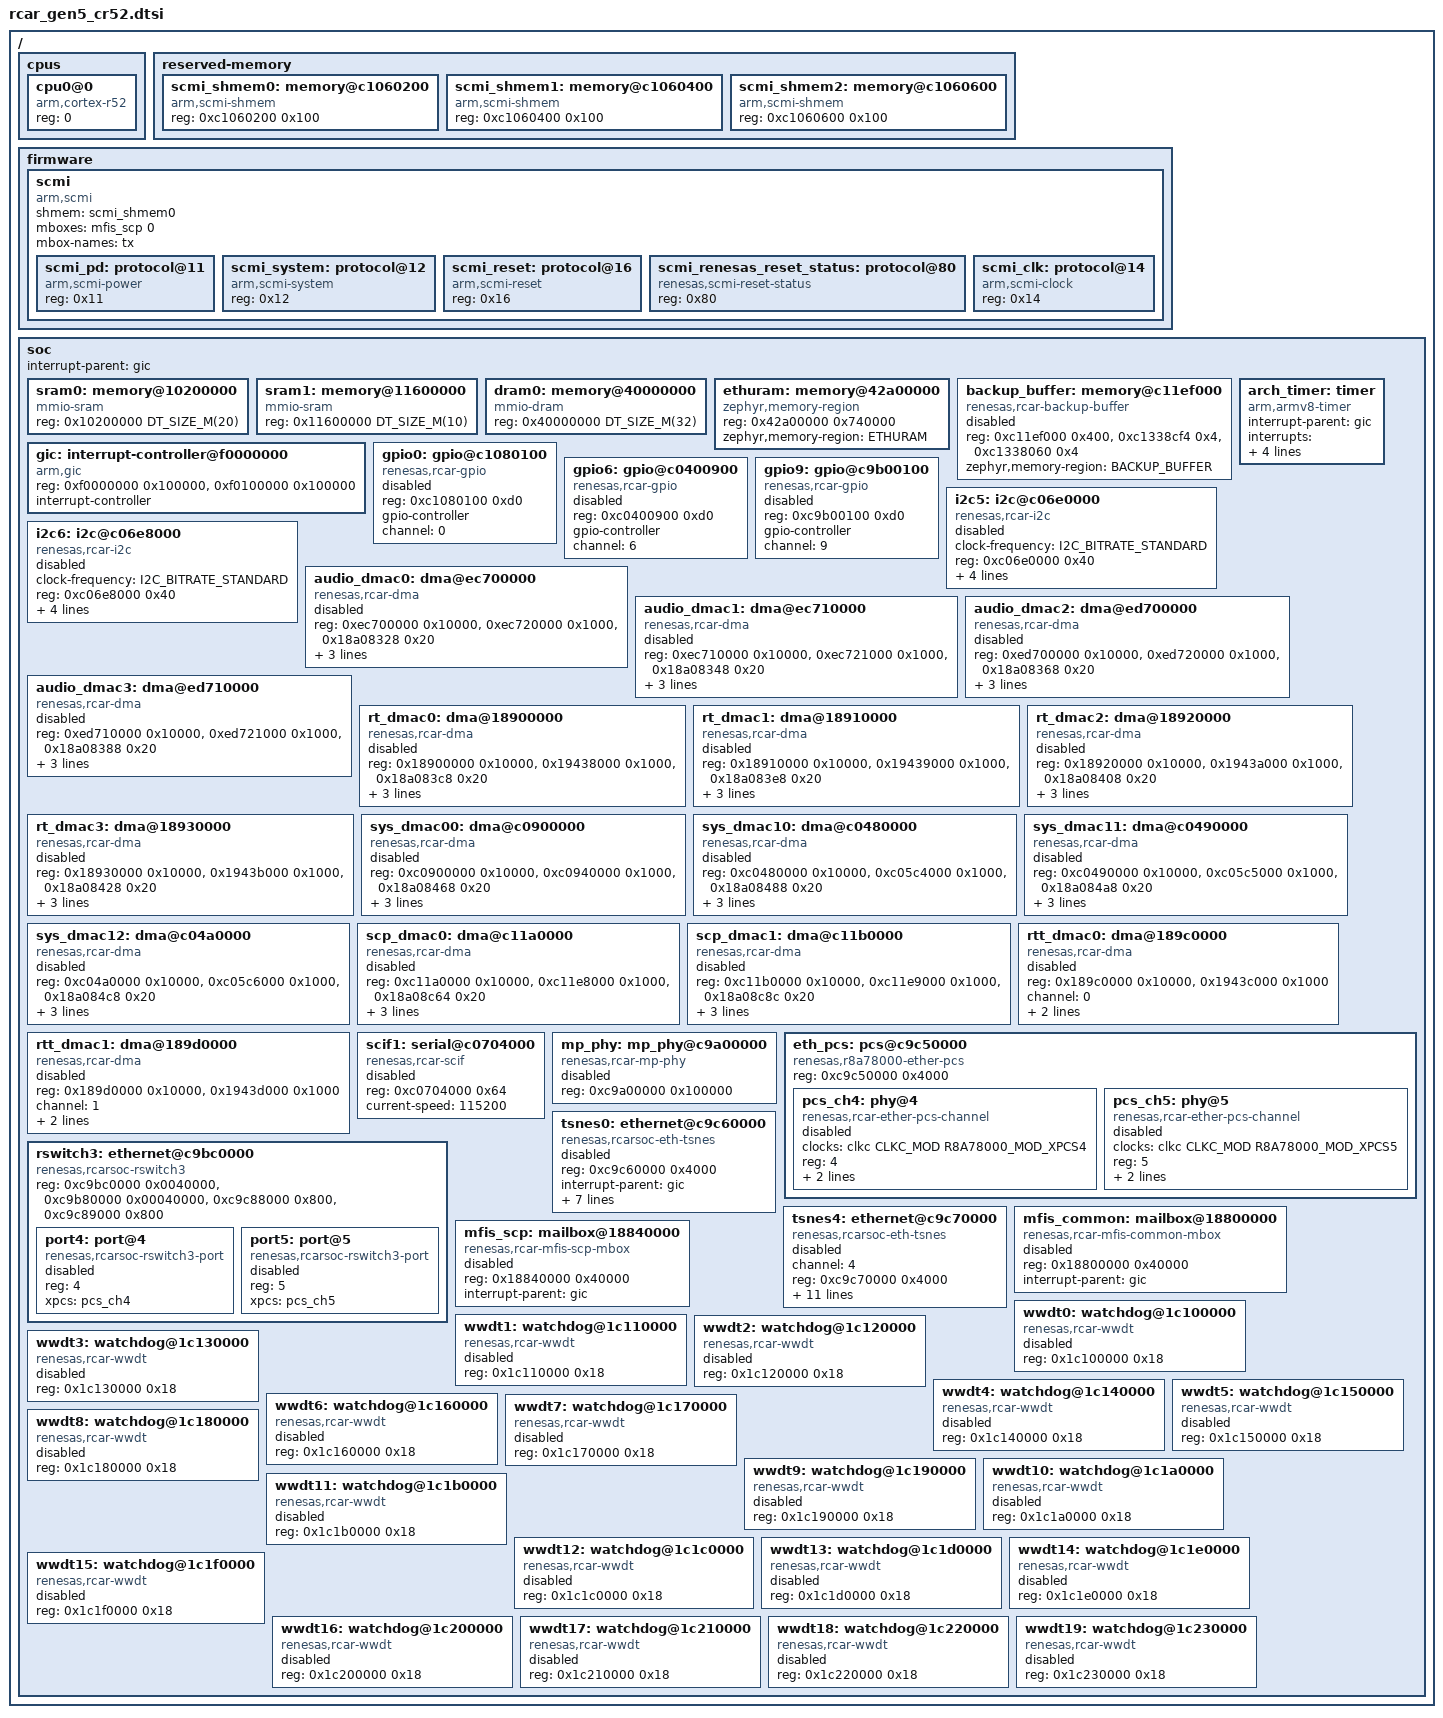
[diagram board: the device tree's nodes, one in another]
/*
 * Copyright (c) 2026 Renesas Electronics Corporation
 *
 * SPDX-License-Identifier: Apache-2.0
 */

#include <arm/armv8-r.dtsi>
#include <zephyr/dt-bindings/dt-util.h>
#include <zephyr/dt-bindings/interrupt-controller/arm-gic.h>
#include <zephyr/dt-bindings/clock/r8a78000_clkc_mdlc.h>
#include <zephyr/dt-bindings/clock/r8a78000_scmi_clock.h>
#include <zephyr/dt-bindings/i2c/i2c.h>
#include <mem.h>

/ {
	cpus {
		#address-cells = <1>;
		#size-cells = <0>;

		cpu0@0 {
			device_type = "cpu";
			compatible = "arm,cortex-r52";
			reg = <0>;
		};
	};

	reserved-memory {
		#address-cells = <1>;
		#size-cells = <1>;

		scmi_shmem0: memory@c1060200 {
			compatible = "arm,scmi-shmem";
			reg = <0xc1060200 0x100>;
		};

		scmi_shmem1: memory@c1060400 {
			compatible = "arm,scmi-shmem";
			reg = <0xc1060400 0x100>;
		};

		scmi_shmem2: memory@c1060600 {
			compatible = "arm,scmi-shmem";
			reg = <0xc1060600 0x100>;
		};
	};

	firmware {
		scmi {
			compatible = "arm,scmi";
			shmem = <&scmi_shmem0>;
			mboxes = <&mfis_scp 0>;
			mbox-names = "tx";

			#address-cells = <1>;
			#size-cells = <0>;

			scmi_pd: protocol@11 {
				compatible = "arm,scmi-power";
				reg = <0x11>;
				#power-domain-cells = <1>;
			};

			scmi_system: protocol@12 {
				compatible = "arm,scmi-system";
				reg = <0x12>;
			};

			scmi_reset: protocol@16 {
				compatible = "arm,scmi-reset";
				reg = <0x16>;
				#reset-cells = <1>;
			};

			scmi_renesas_reset_status: protocol@80 {
				compatible = "renesas,scmi-reset-status";
				reg = <0x80>;
			};

			scmi_clk: protocol@14 {
				compatible = "arm,scmi-clock";
				reg = <0x14>;
				#clock-cells = <1>;
			};
		};
	};

	soc {
		interrupt-parent = <&gic>;

		sram0: memory@10200000 {
			compatible = "mmio-sram";
			reg = <0x10200000 DT_SIZE_M(20)>;
		};

		sram1: memory@11600000 {
			compatible = "mmio-sram";
			reg = <0x11600000 DT_SIZE_M(10)>;
		};

		dram0: memory@40000000 {
			compatible = "mmio-dram";
			reg = <0x40000000 DT_SIZE_M(32)>;
		};

		ethuram: memory@42a00000 {
			compatible = "zephyr,memory-region";
			reg = <0x42a00000 0x740000>;
			zephyr,memory-region = "ETHURAM";
			status = "okay";
		};

		backup_buffer: memory@c11ef000 {
			compatible = "renesas,rcar-backup-buffer", "zephyr,memory-region";
			/* BKBUF, MDLC27PKCPROT1, MDLC27BKBAPR */
			reg = <0xc11ef000 0x400>,
			      <0xc1338cf4 0x4>,
			      <0xc1338060 0x4>;
			reg-names = "bkbuf", "prot", "bkbapr";
			zephyr,memory-region = "BACKUP_BUFFER";
			status = "disabled";
		};

		gic: interrupt-controller@f0000000 {
			compatible = "arm,gic", "arm,gic-v3";
			reg = <0xf0000000 0x100000>,
			      <0xf0100000 0x100000>;
			interrupt-controller;
			#interrupt-cells = <4>;
			status = "okay";
		};

		arch_timer: timer {
			compatible = "arm,armv8-timer";
			interrupt-parent = <&gic>;
			interrupts = <GIC_PPI 13 IRQ_TYPE_LEVEL IRQ_DEFAULT_PRIORITY>,
				     <GIC_PPI 14 IRQ_TYPE_LEVEL IRQ_DEFAULT_PRIORITY>,
				     <GIC_PPI 11 IRQ_TYPE_LEVEL IRQ_DEFAULT_PRIORITY>,
				     <GIC_PPI 10 IRQ_TYPE_LEVEL IRQ_DEFAULT_PRIORITY>;
		};

		gpio0: gpio@c1080100 {
			compatible = "renesas,rcar-gpio";
			reg = <0xc1080100 0xd0>;
			#gpio-cells = <2>;
			gpio-controller;
			channel = <0>;
			status = "disabled";
		};

		gpio6: gpio@c0400900 {
			compatible = "renesas,rcar-gpio";
			reg = <0xc0400900 0xd0>;
			#gpio-cells = <2>;
			gpio-controller;
			channel = <6>;
			status = "disabled";
		};

		gpio9: gpio@c9b00100 {
			compatible = "renesas,rcar-gpio";
			reg = <0xc9b00100 0xd0>;
			#gpio-cells = <2>;
			gpio-controller;
			channel = <9>;
			status = "disabled";
		};

		i2c5: i2c@c06e0000 {
			compatible = "renesas,rcar-i2c";
			clock-frequency = <I2C_BITRATE_STANDARD>;
			#address-cells = <1>;
			#size-cells = <0>;
			reg = <0xc06e0000 0x40>;
			interrupt-parent = <&gic>;
			interrupts = <GIC_SPI 577 IRQ_TYPE_LEVEL
				      IRQ_DEFAULT_PRIORITY>;
			clocks = <&scmi_clk R8A78000_SCMI_CLK_I2C5>;
			status = "disabled";
		};

		i2c6: i2c@c06e8000 {
			compatible = "renesas,rcar-i2c";
			clock-frequency = <I2C_BITRATE_STANDARD>;
			#address-cells = <1>;
			#size-cells = <0>;
			reg = <0xc06e8000 0x40>;
			interrupt-parent = <&gic>;
			interrupts = <GIC_SPI 578 IRQ_TYPE_LEVEL
				      IRQ_DEFAULT_PRIORITY>;
			clocks = <&scmi_clk R8A78000_SCMI_CLK_I2C6>;
			status = "disabled";
		};

		audio_dmac0: dma@ec700000 {
			compatible = "renesas,rcar-dma";
			reg = <0xec700000 0x10000>,
			      <0xec720000 0x1000>,
			      <0x18a08328 0x20>;
			reg-names = "channel", "public", "intsta";
			channel = <0>;
			dma-channels = <16>;
			dma-type = "Audio-DMAC";
			#dma-cells = <2>;
			status = "disabled";
		};

		audio_dmac1: dma@ec710000 {
			compatible = "renesas,rcar-dma";
			reg = <0xec710000 0x10000>,
			      <0xec721000 0x1000>,
			      <0x18a08348 0x20>;
			reg-names = "channel", "public", "intsta";
			channel = <1>;
			dma-channels = <16>;
			dma-type = "Audio-DMAC";
			#dma-cells = <2>;
			status = "disabled";
		};

		audio_dmac2: dma@ed700000 {
			compatible = "renesas,rcar-dma";
			reg = <0xed700000 0x10000>,
			      <0xed720000 0x1000>,
			      <0x18a08368 0x20>;
			reg-names = "channel", "public", "intsta";
			channel = <2>;
			dma-channels = <16>;
			dma-type = "Audio-DMAC";
			#dma-cells = <2>;
			status = "disabled";
		};

		audio_dmac3: dma@ed710000 {
			compatible = "renesas,rcar-dma";
			reg = <0xed710000 0x10000>,
			      <0xed721000 0x1000>,
			      <0x18a08388 0x20>;
			reg-names = "channel", "public", "intsta";
			channel = <3>;
			dma-channels = <16>;
			dma-type = "Audio-DMAC";
			#dma-cells = <2>;
			status = "disabled";
		};

		rt_dmac0: dma@18900000 {
			compatible = "renesas,rcar-dma";
			reg = <0x18900000 0x10000>,
			      <0x19438000 0x1000>,
			      <0x18a083c8 0x20>;
			reg-names = "channel", "public", "intsta";
			channel = <0>;
			dma-channels = <16>;
			dma-type = "RT-DMAC";
			#dma-cells = <2>;
			status = "disabled";
		};

		rt_dmac1: dma@18910000 {
			compatible = "renesas,rcar-dma";
			reg = <0x18910000 0x10000>,
			      <0x19439000 0x1000>,
			      <0x18a083e8 0x20>;
			reg-names = "channel", "public", "intsta";
			channel = <1>;
			dma-channels = <16>;
			dma-type = "RT-DMAC";
			#dma-cells = <2>;
			status = "disabled";
		};

		rt_dmac2: dma@18920000 {
			compatible = "renesas,rcar-dma";
			reg = <0x18920000 0x10000>,
			      <0x1943a000 0x1000>,
			      <0x18a08408 0x20>;
			reg-names = "channel", "public", "intsta";
			channel = <2>;
			dma-channels = <16>;
			dma-type = "RT-DMAC";
			#dma-cells = <2>;
			status = "disabled";
		};

		rt_dmac3: dma@18930000 {
			compatible = "renesas,rcar-dma";
			reg = <0x18930000 0x10000>,
			      <0x1943b000 0x1000>,
			      <0x18a08428 0x20>;
			reg-names = "channel", "public", "intsta";
			channel = <3>;
			dma-channels = <16>;
			dma-type = "RT-DMAC";
			#dma-cells = <2>;
			status = "disabled";
		};

		/* SYS-DMAC type 0, unit 0 */
		sys_dmac00: dma@c0900000 {
			compatible = "renesas,rcar-dma";
			reg = <0xc0900000 0x10000>,
			      <0xc0940000 0x1000>,
			      <0x18a08468 0x20>;
			reg-names = "channel", "public", "intsta";
			channel = <0>;
			dma-channels = <16>;
			dma-type = "SYS-DMAC";
			#dma-cells = <2>;
			status = "disabled";
		};

		/* SYS-DMAC type 1, unit 0 */
		sys_dmac10: dma@c0480000 {
			compatible = "renesas,rcar-dma";
			reg = <0xc0480000 0x10000>,
			      <0xc05c4000 0x1000>,
			      <0x18a08488 0x20>;
			reg-names = "channel", "public", "intsta";
			channel = <1>;
			dma-channels = <16>;
			dma-type = "SYS-DMAC";
			#dma-cells = <2>;
			status = "disabled";
		};

		/* SYS-DMAC type 1, unit 1 */
		sys_dmac11: dma@c0490000 {
			compatible = "renesas,rcar-dma";
			reg = <0xc0490000 0x10000>,
			      <0xc05c5000 0x1000>,
			      <0x18a084a8 0x20>;
			reg-names = "channel", "public", "intsta";
			channel = <2>;
			dma-channels = <16>;
			dma-type = "SYS-DMAC";
			#dma-cells = <2>;
			status = "disabled";
		};

		/* SYS-DMAC type 1, unit 2 */
		sys_dmac12: dma@c04a0000 {
			compatible = "renesas,rcar-dma";
			reg = <0xc04a0000 0x10000>,
			      <0xc05c6000 0x1000>,
			      <0x18a084c8 0x20>;
			reg-names = "channel", "public", "intsta";
			channel = <3>;
			dma-channels = <16>;
			dma-type = "SYS-DMAC";
			#dma-cells = <2>;
			status = "disabled";
		};

		scp_dmac0: dma@c11a0000 {
			compatible = "renesas,rcar-dma";
			reg = <0xc11a0000 0x10000>,
			      <0xc11e8000 0x1000>,
			      <0x18a08c64 0x20>;
			reg-names = "channel", "public", "intsta";
			channel = <0>;
			dma-channels = <16>;
			dma-type = "SCP-DMAC";
			#dma-cells = <2>;
			status = "disabled";
		};

		scp_dmac1: dma@c11b0000 {
			compatible = "renesas,rcar-dma";
			reg = <0xc11b0000 0x10000>,
			      <0xc11e9000 0x1000>,
			      <0x18a08c8c 0x20>;
			reg-names = "channel", "public", "intsta";
			channel = <1>;
			dma-channels = <16>;
			dma-type = "SCP-DMAC";
			#dma-cells = <2>;
			status = "disabled";
		};

		rtt_dmac0: dma@189c0000 {
			compatible = "renesas,rcar-dma";
			reg = <0x189c0000 0x10000>,
			      <0x1943c000 0x1000>;
			reg-names = "channel", "public";
			channel = <0>;
			dma-channels = <16>;
			dma-type = "RTT-DMAC";
			#dma-cells = <2>;
			status = "disabled";
		};

		rtt_dmac1: dma@189d0000 {
			compatible = "renesas,rcar-dma";
			reg = <0x189d0000 0x10000>,
			      <0x1943d000 0x1000>;
			reg-names = "channel", "public";
			channel = <1>;
			dma-channels = <16>;
			dma-type = "RTT-DMAC";
			#dma-cells = <2>;
			status = "disabled";
		};

		scif1: serial@c0704000 {
			compatible = "renesas,rcar-scif";
			reg = <0xc0704000 0x64>;
			current-speed = <115200>;
			status = "disabled";
		};

		mp_phy: mp_phy@c9a00000 {
			compatible = "renesas,rcar-mp-phy";
			reg = <0xc9a00000 0x100000>;
			#phy-cells = <2>;
			status = "disabled";
		};

		eth_pcs: pcs@c9c50000 {
			compatible = "renesas,r8a78000-ether-pcs";
			reg = <0xc9c50000 0x4000>;
			#address-cells = <1>;
			#size-cells = <0>;
			status = "okay";

			pcs_ch4: phy@4 {
				compatible = "renesas,rcar-ether-pcs-channel";
				clocks = <&clkc CLKC_MOD R8A78000_MOD_XPCS4>;
				reg = <4>;
				phys = <&mp_phy 2 0>;
				phy-mode = "usxgmii";
				status = "disabled";
			};

			pcs_ch5: phy@5 {
				compatible = "renesas,rcar-ether-pcs-channel";
				clocks = <&clkc CLKC_MOD R8A78000_MOD_XPCS5>;
				reg = <5>;
				phys = <&mp_phy 2 1>;
				phy-mode = "sgmii";
				status = "disabled";
			};
		};

		rswitch3: ethernet@c9bc0000 {
			compatible = "renesas,rcarsoc-rswitch3";
			#address-cells = <1>;
			#size-cells = <0>;
			reg = <0xc9bc0000 0x0040000>,
			      <0xc9b80000 0x00040000>,
			      <0xc9c88000 0x800>,
			      <0xc9c89000 0x800>;
			reg-names = "base", "secure_base", "gptp_base", "secure_ptp";
			status = "okay";

			port4: port@4 {
				compatible = "renesas,rcarsoc-rswitch3-port";
				reg = <4>;
				xpcs = <&pcs_ch4>;
				status = "disabled";
			};

			port5: port@5 {
				compatible = "renesas,rcarsoc-rswitch3-port";
				reg = <5>;
				xpcs = <&pcs_ch5>;
				status = "disabled";
			};
		};

		tsnes0: ethernet@c9c60000 {
			compatible = "renesas,rcarsoc-eth-tsnes";
			reg = <0xc9c60000 0x4000>;
			reg-names = "tsnes";
			interrupt-parent = <&gic>;

			interrupts = <GIC_SPI 494 IRQ_TYPE_LEVEL IRQ_DEFAULT_PRIORITY>,
				     <GIC_SPI 502 IRQ_TYPE_LEVEL IRQ_DEFAULT_PRIORITY>;
			interrupt-names = "tdis", "tes_int_n";
			clocks = <&clkc CLKC_MOD R8A78000_MOD_TSNTES0>,
				 <&clkc CLKC_CORE R8A78000_CLK_S0D1_HSCN_RSW3_MAIN>,
				 <&clkc CLKC_CORE R8A78000_CLK_S0D4_HSCN_RSW3_MAIN>,
				 <&clkc CLKC_CORE R8A78000_CLK_RSWSUBD1CK_HSCN_RSW3_MAIN>;
			status = "disabled";
		};

		tsnes4: ethernet@c9c70000 {
			compatible = "renesas,rcarsoc-eth-tsnes";
			channel = <4>;
			reg = <0xc9c70000 0x4000>;
			reg-names = "tsnes";
			interrupt-parent = <&gic>;

			interrupts = <GIC_SPI 498 IRQ_TYPE_LEVEL IRQ_DEFAULT_PRIORITY>,
				     <GIC_SPI 506 IRQ_TYPE_LEVEL IRQ_DEFAULT_PRIORITY>;
			interrupt-names = "tdis", "tes_int_n";
			clocks = <&clkc CLKC_MOD R8A78000_MOD_TSNTES0>,
				 <&clkc CLKC_CORE R8A78000_CLK_S0D1_HSCN_RSW3_MAIN>,
				 <&clkc CLKC_CORE R8A78000_CLK_S0D4_HSCN_RSW3_MAIN>,
				 <&clkc CLKC_CORE R8A78000_CLK_RSWSUBD1CK_HSCN_RSW3_MAIN>;
			renesas,rswitch = <&rswitch3>;
			renesas,rswitch-if = <9>;
			renesas,rswitch-forward-ports = <BIT(5)>;
			status = "disabled";
		};

		mfis_common: mailbox@18800000 {
			compatible = "renesas,rcar-mfis-common-mbox";
			reg = <0x18800000 0x40000>;
			interrupt-parent = <&gic>;
			#address-cells = <1>;
			#size-cells = <0>;
			#mbox-cells = <1>;
			status = "disabled";
		};

		mfis_scp: mailbox@18840000 {
			compatible = "renesas,rcar-mfis-scp-mbox";
			reg = <0x18840000 0x40000>;
			interrupt-parent = <&gic>;
			#mbox-cells = <1>;
			status = "disabled";
		};

		wwdt0: watchdog@1c100000 {
			compatible = "renesas,rcar-wwdt";
			reg = <0x1c100000 0x18>;
			status = "disabled";
		};

		wwdt1: watchdog@1c110000 {
			compatible = "renesas,rcar-wwdt";
			reg = <0x1c110000 0x18>;
			status = "disabled";
		};

		wwdt2: watchdog@1c120000 {
			compatible = "renesas,rcar-wwdt";
			reg = <0x1c120000 0x18>;
			status = "disabled";
		};

		wwdt3: watchdog@1c130000 {
			compatible = "renesas,rcar-wwdt";
			reg = <0x1c130000 0x18>;
			status = "disabled";
		};

		wwdt4: watchdog@1c140000 {
			compatible = "renesas,rcar-wwdt";
			reg = <0x1c140000 0x18>;
			status = "disabled";
		};

		wwdt5: watchdog@1c150000 {
			compatible = "renesas,rcar-wwdt";
			reg = <0x1c150000 0x18>;
			status = "disabled";
		};

		wwdt6: watchdog@1c160000 {
			compatible = "renesas,rcar-wwdt";
			reg = <0x1c160000 0x18>;
			status = "disabled";
		};

		wwdt7: watchdog@1c170000 {
			compatible = "renesas,rcar-wwdt";
			reg = <0x1c170000 0x18>;
			status = "disabled";
		};

		wwdt8: watchdog@1c180000 {
			compatible = "renesas,rcar-wwdt";
			reg = <0x1c180000 0x18>;
			status = "disabled";
		};

		wwdt9: watchdog@1c190000 {
			compatible = "renesas,rcar-wwdt";
			reg = <0x1c190000 0x18>;
			status = "disabled";
		};

		wwdt10: watchdog@1c1a0000 {
			compatible = "renesas,rcar-wwdt";
			reg = <0x1c1a0000 0x18>;
			status = "disabled";
		};

		wwdt11: watchdog@1c1b0000 {
			compatible = "renesas,rcar-wwdt";
			reg = <0x1c1b0000 0x18>;
			status = "disabled";
		};

		wwdt12: watchdog@1c1c0000 {
			compatible = "renesas,rcar-wwdt";
			reg = <0x1c1c0000 0x18>;
			status = "disabled";
		};

		wwdt13: watchdog@1c1d0000 {
			compatible = "renesas,rcar-wwdt";
			reg = <0x1c1d0000 0x18>;
			status = "disabled";
		};

		wwdt14: watchdog@1c1e0000 {
			compatible = "renesas,rcar-wwdt";
			reg = <0x1c1e0000 0x18>;
			status = "disabled";
		};

		wwdt15: watchdog@1c1f0000 {
			compatible = "renesas,rcar-wwdt";
			reg = <0x1c1f0000 0x18>;
			status = "disabled";
		};

		wwdt16: watchdog@1c200000 {
			compatible = "renesas,rcar-wwdt";
			reg = <0x1c200000 0x18>;
			status = "disabled";
		};

		wwdt17: watchdog@1c210000 {
			compatible = "renesas,rcar-wwdt";
			reg = <0x1c210000 0x18>;
			status = "disabled";
		};

		wwdt18: watchdog@1c220000 {
			compatible = "renesas,rcar-wwdt";
			reg = <0x1c220000 0x18>;
			status = "disabled";
		};

		wwdt19: watchdog@1c230000 {
			compatible = "renesas,rcar-wwdt";
			reg = <0x1c230000 0x18>;
			status = "disabled";
		};
	};
};
